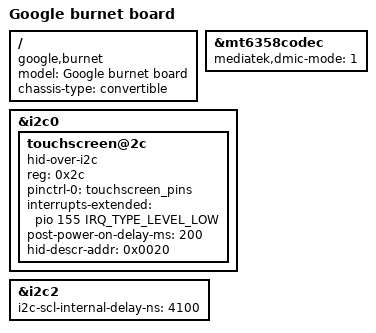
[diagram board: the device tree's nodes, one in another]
// SPDX-License-Identifier: (GPL-2.0 OR MIT)
/*
 * Copyright 2021 Google LLC
 */

/dts-v1/;
#include "mt8183-kukui-jacuzzi.dtsi"
#include "mt8183-kukui-audio-ts3a227e-max98357a.dtsi"

/ {
	model = "Google burnet board";
	chassis-type = "convertible";
	compatible = "google,burnet", "mediatek,mt8183";
};

&mt6358codec {
	mediatek,dmic-mode = <1>; /* one-wire */
};

&i2c0 {
	touchscreen@2c {
		compatible = "hid-over-i2c";
		reg = <0x2c>;
		pinctrl-names = "default";
		pinctrl-0 = <&touchscreen_pins>;
		interrupts-extended = <&pio 155 IRQ_TYPE_LEVEL_LOW>;

		post-power-on-delay-ms = <200>;
		hid-descr-addr = <0x0020>;
	};
};

&i2c2 {
	i2c-scl-internal-delay-ns = <4100>;
};
